# STM32L443VCT6 register map
File version: 1.0
Registers are 32-bit, access not given, reset 0x0 unless marked. A register's access mark holds for its fields unless they carry their own. Offsets are from the block's base; [hi:lo] are bit positions; {n}, {i} and the like mark numbered series.

## OPAMP
Base 0x40007800
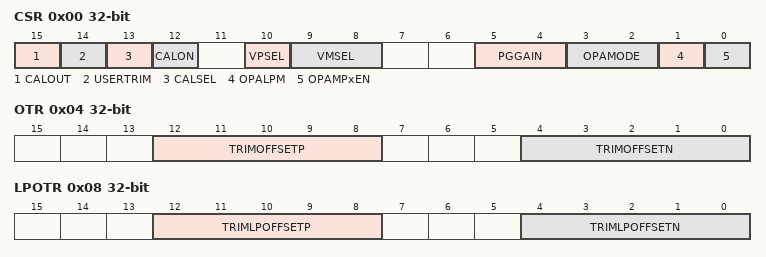
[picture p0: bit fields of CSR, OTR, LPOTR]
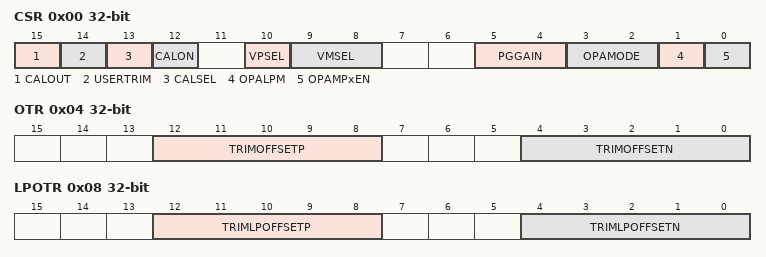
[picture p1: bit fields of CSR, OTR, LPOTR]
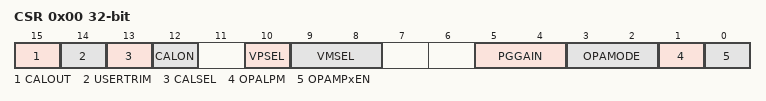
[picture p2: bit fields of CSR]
0x00 CSR
  [15] CALOUT, [14] USERTRIM, [13] CALSEL, [12] CALON, [10] VPSEL, [9:8] VMSEL, [5:4] PGGAIN, [3:2] OPAMODE, [1] OPALPM, [0] OPAMPxEN
0x04 OTR
  [12:8] TRIMOFFSETP, [4:0] TRIMOFFSETN
0x08 LPOTR
  [12:8] TRIMLPOFFSETP, [4:0] TRIMLPOFFSETN

## OPAMP1
Base 0x40007800
0x00 CSR
  [15] CALOUT, [14] USERTRIM, [13] CALSEL, [12] CALON, [10] VPSEL, [9:8] VMSEL, [5:4] PGGAIN, [3:2] OPAMODE, [1] OPALPM, [0] OPAMPxEN
0x04 OTR
  [12:8] TRIMOFFSETP, [4:0] TRIMOFFSETN
0x08 LPOTR
  [12:8] TRIMLPOFFSETP, [4:0] TRIMLPOFFSETN

## OPAMP1_COMMON
Base 0x40007800
0x00 CSR
  [15] CALOUT, [14] USERTRIM, [13] CALSEL, [12] CALON, [10] VPSEL, [9:8] VMSEL, [5:4] PGGAIN, [3:2] OPAMODE, [1] OPALPM, [0] OPAMPxEN

## LPTIM1
Base 0x40007C00
Same registers: LPTIM2 0x40009400
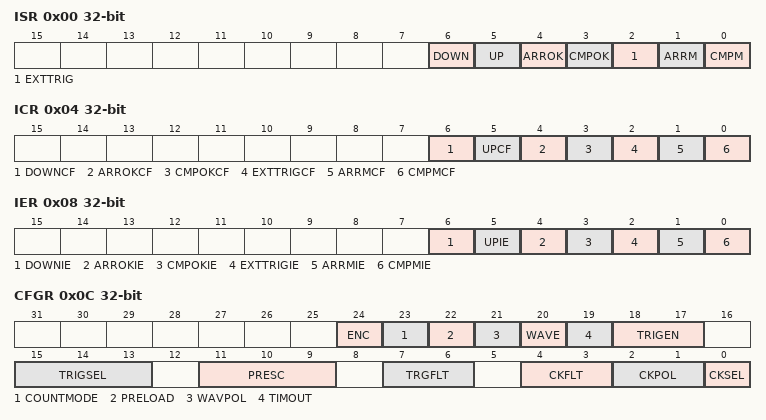
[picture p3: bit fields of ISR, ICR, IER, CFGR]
0x00 ISR
  [6] DOWN, [5] UP, [4] ARROK, [3] CMPOK, [2] EXTTRIG, [1] ARRM, [0] CMPM
0x04 ICR
  [6] DOWNCF, [5] UPCF, [4] ARROKCF, [3] CMPOKCF, [2] EXTTRIGCF, [1] ARRMCF, [0] CMPMCF
0x08 IER
  [6] DOWNIE, [5] UPIE, [4] ARROKIE, [3] CMPOKIE, [2] EXTTRIGIE, [1] ARRMIE, [0] CMPMIE
0x0C CFGR
  [24] ENC, [23] COUNTMODE, [22] PRELOAD, [21] WAVPOL, [20] WAVE, [19] TIMOUT, [18:17] TRIGEN, [15:13] TRIGSEL, [11:9] PRESC, [7:6] TRGFLT, [4:3] CKFLT, [2:1] CKPOL, [0] CKSEL
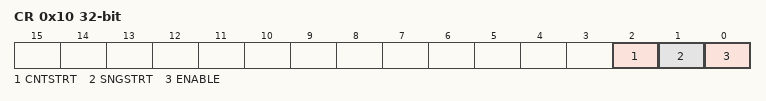
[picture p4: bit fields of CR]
0x10 CR
  [2] CNTSTRT, [1] SNGSTRT, [0] ENABLE
0x14 CMP
  [15:0] CMP
0x18 ARR
  [15:0] ARR
0x1C CNT
  [15:0] CNT
0x20 OR
  [1:0] OR

## SWPMI1
Base 0x40008800
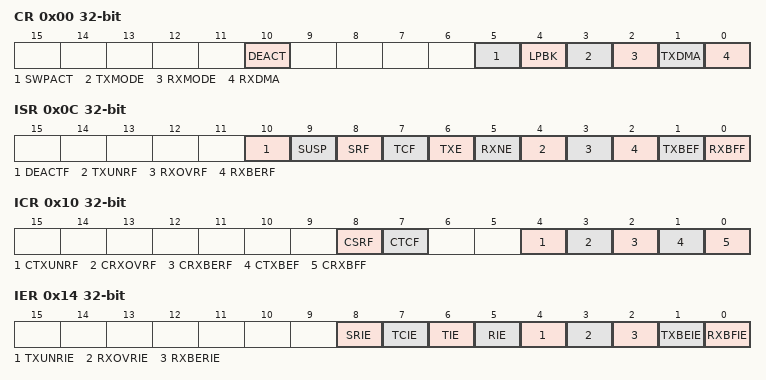
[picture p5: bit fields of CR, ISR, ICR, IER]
0x00 CR
  [10] DEACT, [5] SWPACT, [4] LPBK, [3] TXMODE, [2] RXMODE, [1] TXDMA, [0] RXDMA
0x04 BRR
  [5:0] BR
0x0C ISR
  [10] DEACTF, [9] SUSP, [8] SRF, [7] TCF, [6] TXE, [5] RXNE, [4] TXUNRF, [3] RXOVRF, [2] RXBERF, [1] TXBEF, [0] RXBFF
0x10 ICR
  [8] CSRF, [7] CTCF, [4] CTXUNRF, [3] CRXOVRF, [2] CRXBERF, [1] CTXBEF, [0] CRXBFF
0x14 IER
  [8] SRIE, [7] TCIE, [6] TIE, [5] RIE, [4] TXUNRIE, [3] RXOVRIE, [2] RXBERIE, [1] TXBEIE, [0] RXBFIE
0x18 RFL
  [1:0] RFL_0_1
0x1C TDR
  [31:0] TD
0x20 RDR
  [31:0] RD
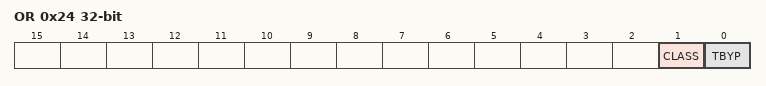
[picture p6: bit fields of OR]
0x24 OR
  [1] CLASS, [0] TBYP

## SYSCFG
Base 0x40010000
0x00 MEMRMP
  [2:0] MEM_MODE
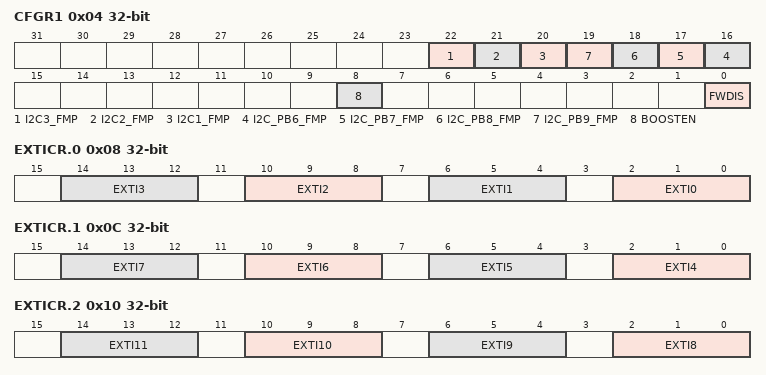
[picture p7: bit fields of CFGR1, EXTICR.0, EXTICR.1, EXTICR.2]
0x04 CFGR1
  [22] I2C3_FMP, [21] I2C2_FMP, [20] I2C1_FMP, [n+10] I2C_PB{n}_FMP (n=6..9), [8] BOOSTEN, [0] FWDIS
0x08 EXTICR.0
  [4n+2:4n] EXTI{n} (n=0..3)
0x0C EXTICR.1
  [4n-14:4n-16] EXTI{n} (n=4..7)
0x10 EXTICR.2
  [4n-30:4n-32] EXTI{n} (n=8..11)
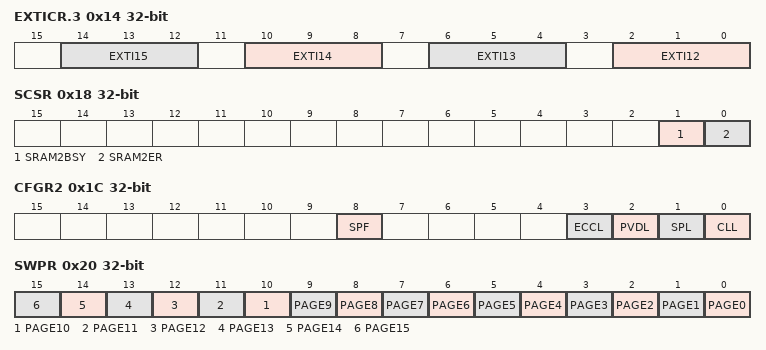
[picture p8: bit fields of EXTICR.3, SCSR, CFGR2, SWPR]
0x14 EXTICR.3
  [4n-46:4n-48] EXTI{n} (n=12..15)
0x18 SCSR
  [1] SRAM2BSY, [0] SRAM2ER
0x1C CFGR2
  [8] SPF, [3] ECCL, [2] PVDL, [1] SPL, [0] CLL
0x20 SWPR
  [n] PAGE{n} (n=0..15)
0x24 SKR
  [7:0] KEY

## VREFBUF
Base 0x40010030
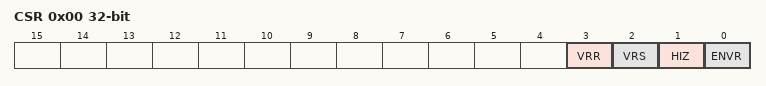
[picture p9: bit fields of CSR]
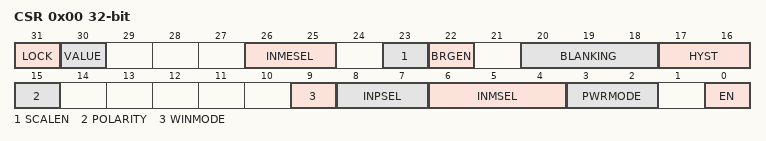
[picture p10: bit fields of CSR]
0x00 CSR
  [3] VRR, [2] VRS, [1] HIZ, [0] ENVR
0x04 CCR
  [5:0] TRIM

## COMP1
Base 0x40010200
Same registers: COMP2 0x40010204, COMP12_COMMON 0x40010204
0x00 CSR
  [31] LOCK, [30] VALUE, [26:25] INMESEL, [23] SCALEN, [22] BRGEN, [20:18] BLANKING, [17:16] HYST, [15] POLARITY, [9] WINMODE, [8:7] INPSEL, [6:4] INMSEL, [3:2] PWRMODE, [0] EN

## EXTI
Base 0x40010400
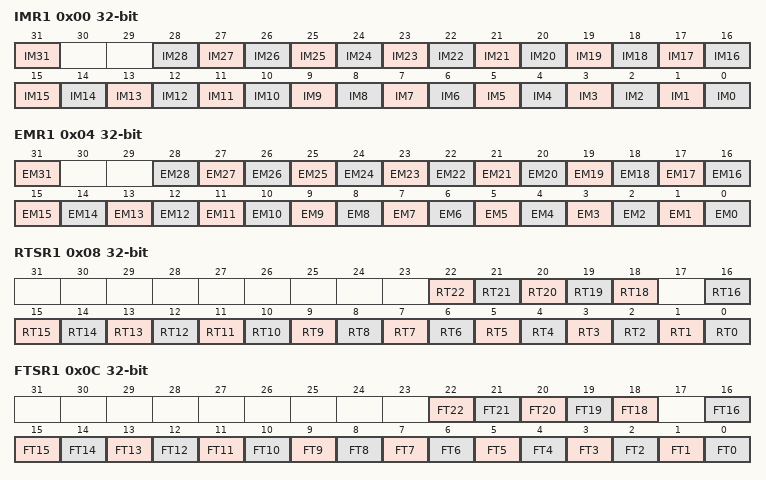
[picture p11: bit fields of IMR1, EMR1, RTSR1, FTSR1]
0x00 IMR1
  [31] IM31, [n] IM{n} (n=0..28)
0x04 EMR1
  [31] EM31, [n] EM{n} (n=0..28)
0x08 RTSR1
  [n] RT{n} (n=18..22), [n] RT{n} (n=0..16)
0x0C FTSR1
  [n] FT{n} (n=18..22), [n] FT{n} (n=0..16)
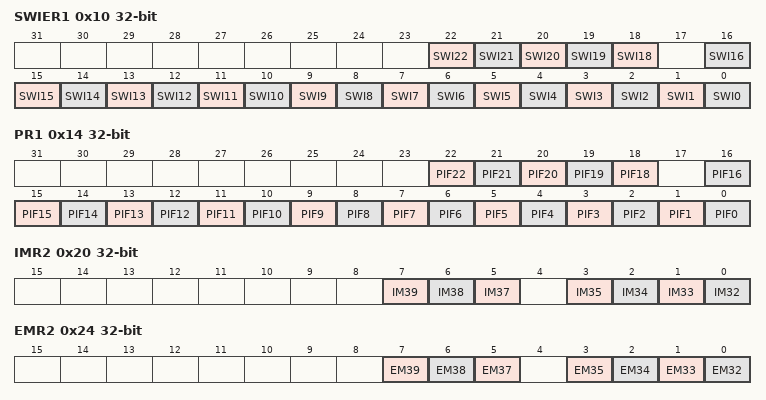
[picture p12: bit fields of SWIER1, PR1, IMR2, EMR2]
0x10 SWIER1
  [n] SWI{n} (n=18..22), [n] SWI{n} (n=0..16)
0x14 PR1
  [n] PIF{n} (n=18..22), [n] PIF{n} (n=0..16)
0x20 IMR2
  [7] IM39, [6] IM38, [5] IM37, [n-32] IM{n} (n=32..35)
0x24 EMR2
  [7] EM39, [6] EM38, [5] EM37, [n-32] EM{n} (n=32..35)
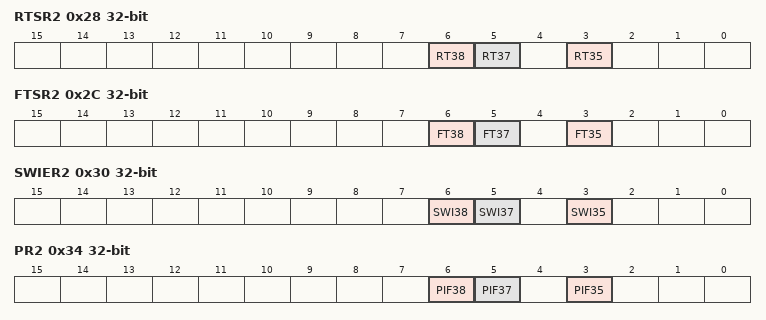
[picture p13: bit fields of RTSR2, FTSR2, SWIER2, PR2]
0x28 RTSR2
  [6] RT38, [5] RT37, [3] RT35
0x2C FTSR2
  [6] FT38, [5] FT37, [3] FT35
0x30 SWIER2
  [6] SWI38, [5] SWI37, [3] SWI35
0x34 PR2
  [6] PIF38, [5] PIF37, [3] PIF35

## FIREWALL
Base 0x40011C00
0x00 CSSA
0x04 CSL
0x08 NVDSSA
0x0C NVDSL
0x10 VDSSA
0x14 VDSL
0x20 CR
